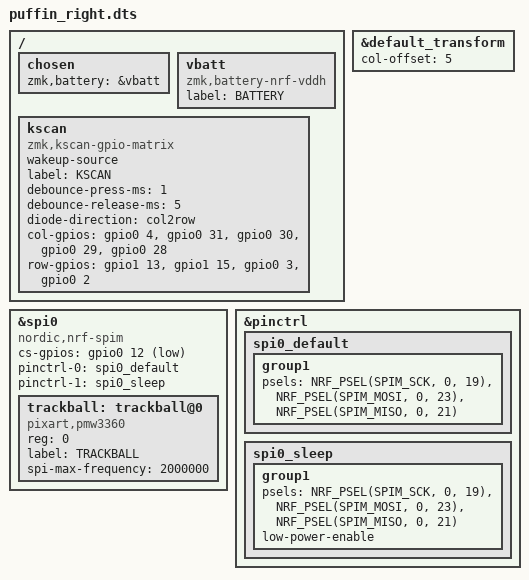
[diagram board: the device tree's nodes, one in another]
/*
 * Copyright (c) 2020 The ZMK Contributors
 *
 * SPDX-License-Identifier: MIT
 */

#include "puffin.dtsi"
#include <drivers/gpio.h>                                                                                                                                                     
#include <drivers/spi.h>

/ {

	chosen {
		zmk,battery = &vbatt;
	};

	vbatt: vbatt {
		compatible = "zmk,battery-nrf-vddh";
		label = "BATTERY";
	};

	kscan: kscan {
		compatible = "zmk,kscan-gpio-matrix";
		wakeup-source;
		label = "KSCAN";
		debounce-press-ms = <1>;
		debounce-release-ms = <5>;

		diode-direction = "col2row";

		col-gpios
			= <&gpio0 4 (GPIO_ACTIVE_HIGH)>
			, <&gpio0 31  (GPIO_ACTIVE_HIGH)>
			, <&gpio0 30 (GPIO_ACTIVE_HIGH)>
			, <&gpio0 29 (GPIO_ACTIVE_HIGH)>
			, <&gpio0 28 (GPIO_ACTIVE_HIGH)>
			;
		row-gpios
			= <&gpio1 13 (GPIO_ACTIVE_HIGH | GPIO_PULL_DOWN)>
			, <&gpio1 15 (GPIO_ACTIVE_HIGH | GPIO_PULL_DOWN)>
			, <&gpio0 3 (GPIO_ACTIVE_HIGH | GPIO_PULL_DOWN)>
			, <&gpio0 2 (GPIO_ACTIVE_HIGH | GPIO_PULL_DOWN)>
			;
	};
	

};

&default_transform {
    col-offset = <5>;
};

&spi0 {
	compatible = "nordic,nrf-spim";
	cs-gpios = <&gpio0 12 GPIO_ACTIVE_LOW>;
	status = "okay";
	pinctrl-0 = <&spi0_default>;
	pinctrl-1 = <&spi0_sleep>;
	pinctrl-names = "default", "sleep";
	trackball: trackball@0 {
		compatible = "pixart,pmw3360";
		status = "okay";
		reg = <0>;
		label = "TRACKBALL";
		spi-max-frequency = <2000000>;
		//duplex = <2048>; // required by 3-wire spi
	};
};

&pinctrl {
    spi0_default: spi0_default {
        group1 {
            psels = <NRF_PSEL(SPIM_SCK, 0, 19)>,
                <NRF_PSEL(SPIM_MOSI, 0, 23)>,
                <NRF_PSEL(SPIM_MISO, 0, 21)>;
        };
    };

    spi0_sleep: spi0_sleep {
        group1 {
            psels = <NRF_PSEL(SPIM_SCK, 0, 19)>,
                <NRF_PSEL(SPIM_MOSI, 0, 23)>,
                <NRF_PSEL(SPIM_MISO, 0, 21)>;
            low-power-enable;
        };
    };
}; 



